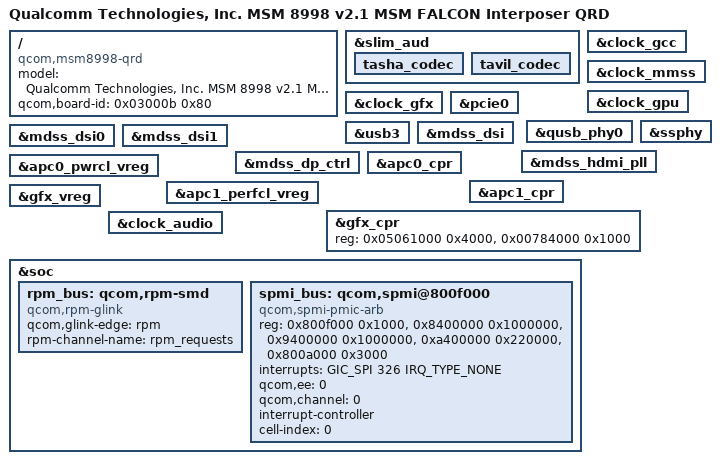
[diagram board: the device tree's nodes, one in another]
/* Copyright (c) 2016, The Linux Foundation. All rights reserved.
 *
 * This program is free software; you can redistribute it and/or modify
 * it under the terms of the GNU General Public License version 2 and
 * only version 2 as published by the Free Software Foundation.
 *
 * This program is distributed in the hope that it will be useful,
 * but WITHOUT ANY WARRANTY; without even the implied warranty of
 * MERCHANTABILITY or FITNESS FOR A PARTICULAR PURPOSE.  See the
 * GNU General Public License for more details.
 */


/dts-v1/;

#include "msm8998-v2.1-interposer-msmfalcon-qrd.dtsi"

/ {
	model =
	"Qualcomm Technologies, Inc. MSM 8998 v2.1 MSM FALCON Interposer QRD";
	compatible = "qcom,msm8998-qrd", "qcom,msm8998", "qcom,qrd";
	qcom,board-id = <0x03000b 0x80>;
};

&slim_aud {
	tasha_codec {
		/delete-property/cdc-vdd-buck-supply;
		/delete-property/cdc-buck-sido-supply;
		/delete-property/cdc-vdd-tx-h-supply;
		/delete-property/cdc-vdd-rx-h-supply;
		/delete-property/cdc-vddpx-1-supply;
	};

	tavil_codec {
		/delete-property/cdc-vdd-buck-supply;
		/delete-property/cdc-buck-sido-supply;
		/delete-property/cdc-vdd-tx-h-supply;
		/delete-property/cdc-vdd-rx-h-supply;
		/delete-property/cdc-vddpx-1-supply;
	};
};

&clock_gcc {
	/delete-property/vdd_dig-supply;
	/delete-property/vdd_dig_ao-supply;
};

&clock_mmss {
	/delete-property/vdd_dig-supply;
	/delete-property/vdd_mmsscc_mx-supply;
};

&clock_gpu {
	/delete-property/vdd_dig-supply;
};

&clock_gfx {
	/delete-property/vdd_mx-supply;
	/delete-property/vdd_gpu_mx-supply;
};

&pcie0 {
	/delete-property/vreg-1.8-supply;
	/delete-property/vreg-0.9-supply;
	/delete-property/vreg-cx-supply;
};

&qusb_phy0 {
	/delete-property/vdd-supply;
	/delete-property/vdda18-supply;
	/delete-property/vdda33-supply;
};

&ssphy {
	/delete-property/vdd-supply;
	/delete-property/core-supply;
};

&usb3 {
	/delete-property/extcon;
};

&mdss_dsi {
	/delete-property/vdda-1p2-supply;
	/delete-property/vdda-0p9-supply;
};

&mdss_dsi0 {
	/delete-property/wqhd-vddio-supply;
	/delete-property/lab-supply;
	/delete-property/ibb-supply;
};

&mdss_dsi1 {
	/delete-property/wqhd-vddio-supply;
	/delete-property/lab-supply;
	/delete-property/ibb-supply;
};

&mdss_hdmi_pll {
	/delete-property/vdda-pll-supply;
	/delete-property/vdda-phy-supply;
};

&mdss_dp_ctrl {
	/delete-property/vdda-1p2-supply;
	/delete-property/vdda-0p9-supply;
	/delete-property/qcom,dp-usbpd-detection;
};

&apc0_cpr {
	 /* disable aging and closed-loop */
	/delete-property/vdd-supply;
	/delete-property/qcom,cpr-enable;
	/delete-property/qcom,cpr-hw-closed-loop;
	/delete-property/qcom,cpr-aging-ref-voltage;
};

&apc0_pwrcl_vreg {
	/delete-property/qcom,cpr-aging-max-voltage-adjustment;
	/delete-property/qcom,cpr-aging-ref-corner;
	/delete-property/qcom,cpr-aging-ro-scaling-factor;
	/delete-property/qcom,allow-aging-voltage-adjustment;
	/delete-property/qcom,allow-aging-open-loop-voltage-adjustment;
};

&apc1_cpr {
	/* disable aging and closed-loop */
	/delete-property/vdd-supply;
	/delete-property/qcom,cpr-enable;
	/delete-property/qcom,cpr-hw-closed-loop;
	/delete-property/qcom,cpr-aging-ref-voltage;
};

&apc1_perfcl_vreg {
	/delete-property/qcom,cpr-aging-max-voltage-adjustment;
	/delete-property/qcom,cpr-aging-ref-corner;
	/delete-property/qcom,cpr-aging-ro-scaling-factor;
	/delete-property/qcom,allow-aging-voltage-adjustment;
	/delete-property/qcom,allow-aging-open-loop-voltage-adjustment;
};

&gfx_cpr {
	reg = <0x05061000 0x4000>,
		<0x00784000 0x1000>;
	reg-names = "cpr_ctrl", "fuse_base";

	/* disable aging and closed-loop */
	/delete-property/vdd-supply;
	/delete-property/qcom,cpr-enable;
	/delete-property/qcom,cpr-aging-ref-voltage;
	/delete-property/qcom,cpr-aging-allowed-reg-mask;
	/delete-property/qcom,cpr-aging-allowed-reg-value;
};

&gfx_vreg {
	/delete-property/qcom,cpr-aging-max-voltage-adjustment;
	/delete-property/qcom,cpr-aging-ref-corner;
	/delete-property/qcom,cpr-aging-ro-scaling-factor;
	/delete-property/qcom,allow-aging-voltage-adjustment;
	/delete-property/qcom,allow-aging-open-loop-voltage-adjustment;
};

&clock_audio {
	/delete-property/qcom,audio-ref-clk-gpio;
};

&soc {
	/delete-node/qcom,csid@ca30000;
	/delete-node/qcom,csid@ca30400;
	/delete-node/qcom,csid@ca30800;
	/delete-node/qcom,csid@ca30c00;

	/delete-node/qcom,lpass@17300000;
	/delete-node/qcom,mss@4080000;
	/delete-node/qcom,spss@1d00000;
	/delete-node/qcom,bcl;
	/delete-node/qcom,msm-thermal;
	/delete-node/qcom,ssc@5c00000;
	/delete-node/qcom,icnss@18800000;
	/delete-node/qcom,wil6210;
	/delete-node/qcom,rpm-smd;
	/delete-node/qcom,spmi@800f000;


	rpm_bus: qcom,rpm-smd {
		compatible = "qcom,rpm-glink";
		qcom,glink-edge = "rpm";
		rpm-channel-name = "rpm_requests";
	};

	spmi_bus: qcom,spmi@800f000 {
		compatible = "qcom,spmi-pmic-arb";
		reg =   <0x800f000 0x1000>,
			<0x8400000 0x1000000>,
			<0x9400000 0x1000000>,
			<0xa400000 0x220000>,
			<0x800a000 0x3000>;
		reg-names = "core", "chnls", "obsrvr", "intr", "cnfg";
		interrupt-names = "periph_irq";
		interrupts = <GIC_SPI 326 IRQ_TYPE_NONE>;
		qcom,ee = <0>;
		qcom,channel = <0>;
		#address-cells = <2>;
		#size-cells = <0>;
		interrupt-controller;
		#interrupt-cells = <4>;
		cell-index = <0>;
	};
};

#include "msm-pmfalcon.dtsi"
#include "msm-pm2falcon.dtsi"
#include "msmfalcon-regulator.dtsi"
